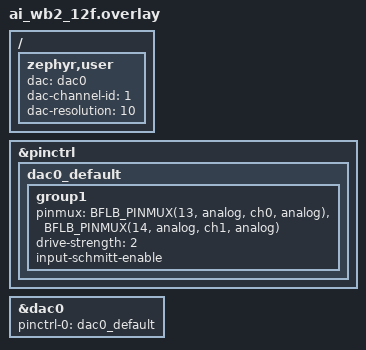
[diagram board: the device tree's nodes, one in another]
/*
 * Copyright (c) 2024 MASSDRIVER EI
 *
 * SPDX-License-Identifier: Apache-2.0
 */


/ {
	zephyr,user {
		dac = <&dac0>;
		dac-channel-id = <1>;
		dac-resolution = <10>;
	};
};

&pinctrl {
	dac0_default: dac0_default {
		group1 {
			pinmux = <BFLB_PINMUX(13, analog, ch0, analog)>,
			<BFLB_PINMUX(14, analog, ch1, analog)>;
			drive-strength = <2>;
			input-schmitt-enable;
		};
	};
};

&dac0 {
	status = "okay";

	pinctrl-0 = <&dac0_default>;
	pinctrl-names = "default";
};
